# CPSW0_NUSS_SS register map
Vendor: Texas Instruments
Peripheral module from a debugger description file (folder J7VCL).
Registers are 32-bit, read-only, reset 0x0 unless marked. A register's access mark holds for its fields unless they carry their own. Offsets are as the file gives them; lines under a group give offsets from that group; [hi:lo] are bit positions; {n}, {i} and the like mark numbered series; 'fields as' and 'values as' point back to an identical list; <NAME> marks a mode.

## CPSW0_NUSS_SS
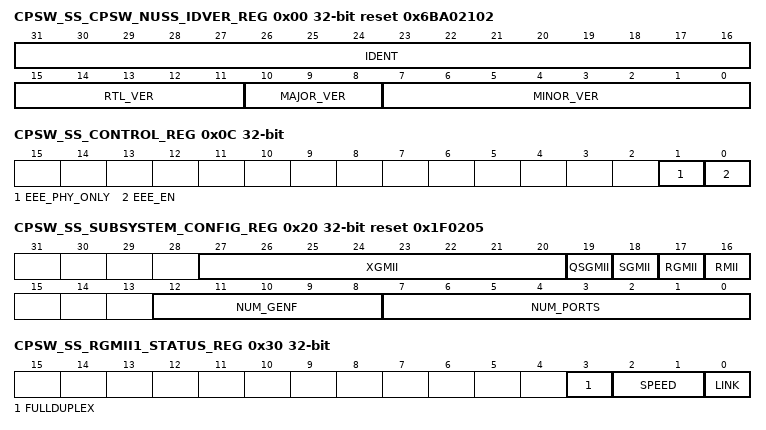
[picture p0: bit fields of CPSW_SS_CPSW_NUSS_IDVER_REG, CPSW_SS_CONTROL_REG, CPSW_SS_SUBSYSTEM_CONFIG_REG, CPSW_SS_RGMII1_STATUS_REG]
0x00 CPSW_SS_CPSW_NUSS_IDVER_REG reset 0x6BA02102 — ID Version Register.
  [31:16] IDENT — Identification value
  [15:11] RTL_VER — RTL version value
  [10:8] MAJOR_VER — Major version value
  [7:0] MINOR_VER — Minor version value
0x04 CPSW_SS_SYNCE_COUNT_REG rw — SyncE Count Register
  [31:0] SYNCE_CNT — Sync E Count Value
0x08 CPSW_SS_SYNCE_MUX_REG rw — SyncE Mux Register
  [5:0] SYNCE_SEL — Sync E Select Value
0x0C CPSW_SS_CONTROL_REG rw — Control Register
  [1] EEE_PHY_ONLY — Energy Efficient Enable Phy Only Mode:
  [0] EEE_EN — Energy Efficient Ethernet Enable:
0x10 CPSW_SS_SGMII_NON_FIBER_MODE_REG rw reset 0xF — SGMII NON FIBER Mode Register
  [3:0] SGMII_NON_FIBER_MODE — This register bit goes to the CPSGMII mode input only
0x14 CPSW_SS_SERDES_RESET_ISO_REG rw — SyncE Mux Register.
  [3:0] SERDES_RESET_ISO — These bits control whether the SERDES ignores the hard reset for isolation or not
0x1C CPSW_SS_SUBSSYSTEM_STATUS_REG — Subsystem Status Register.
  [0] EEE_CLKSTOP_ACK — Energy Efficient Ethernet clockstop acknowledge from CPSW.
0x20 CPSW_SS_SUBSYSTEM_CONFIG_REG reset 0x1F0205 — Return to the . Subsystem Configuration Register
  [27:20] XGMII — The Number of XGMII Ports included in the CPSW_NUSS
  [19] QSGMII — QSGMII is included in the CPSW_NUSS
  [18] SGMII — SGMII is included in the CPSW_NUSS
  [17] RGMII — RGMII is included in the CPSW_NUSS
  [16] RMII — RMII is included in the CPSW_NUSS
  [12:8] NUM_GENF — The number of CPTS GENF outputs
  [7:0] NUM_PORTS — The total number of ports including the host port 0
0x30 CPSW_SS_RGMII1_STATUS_REG — RGMII Port 1 Status Register.
  [3] FULLDUPLEX — RGMII Port 1 full duplex:
  [2:1] SPEED — RGMII Port 1 speed:
  [0] LINK — RGMII Port 1 link indicator:
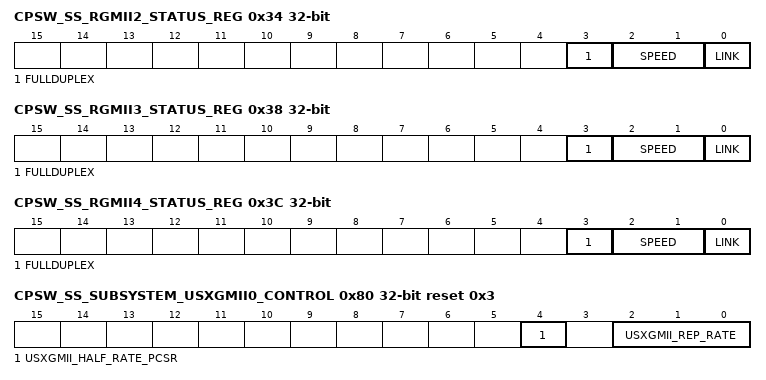
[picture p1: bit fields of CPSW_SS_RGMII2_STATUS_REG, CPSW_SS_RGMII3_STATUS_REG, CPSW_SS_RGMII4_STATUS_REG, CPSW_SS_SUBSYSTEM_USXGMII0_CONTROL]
0x34 CPSW_SS_RGMII2_STATUS_REG — RGMII Port 2 Status Register.
  [3] FULLDUPLEX — RGMII Port 2 full dulex:
  [2:1] SPEED — RGMII Port 2 speed:
  [0] LINK — RGMII Port 2 link indicator:
0x38 CPSW_SS_RGMII3_STATUS_REG — RGMII 3 Port Status Register.
  [3] FULLDUPLEX — RGMII Port 3 full dulex:
  [2:1] SPEED — RGMII Port 3 speed:
  [0] LINK — RGMII Port 3 link indicator:
0x3C CPSW_SS_RGMII4_STATUS_REG — RGMII Port 4 Status Register.
  [3] FULLDUPLEX — RGMII Port 4 full dulex:
  [2:1] SPEED — RGMII Port 4 speed:
  [0] LINK — RGMII Port 4 link indicator:
0x60 CPSW_SS_QSGMII_CONTROL_REG rw — QSGMII Control Register.
  [0] Q0_RDCD — QSGMII0 Running Disparity Check Disable
0x64 CPSW_SS_QSGMII_STATUS_REG — QSGMII Status Register.
  [0] Q0_RX_SYNC — QSGMII0 RX Sync Detected
0x74 CPSW_SS_STATUS_XGMII_LINK_REG — XGMII Link Status Register.
  [0] XGMII1_LINK — Port 1 XGMII Link Indicator
0x78 CPSW_SS_STATUS_SGMII_LINK_REG — SGMII Link Status Register.
  [0] SGMII1_LINK — Port 1 SGMII Link Indicator
0x80 CPSW_SS_SUBSYSTEM_USXGMII0_CONTROL rw reset 0x3 — Return to the . USXGMII0 Control Register
  [4] USXGMII_HALF_RATE_PCSR, [2:0] USXGMII_REP_RATE
